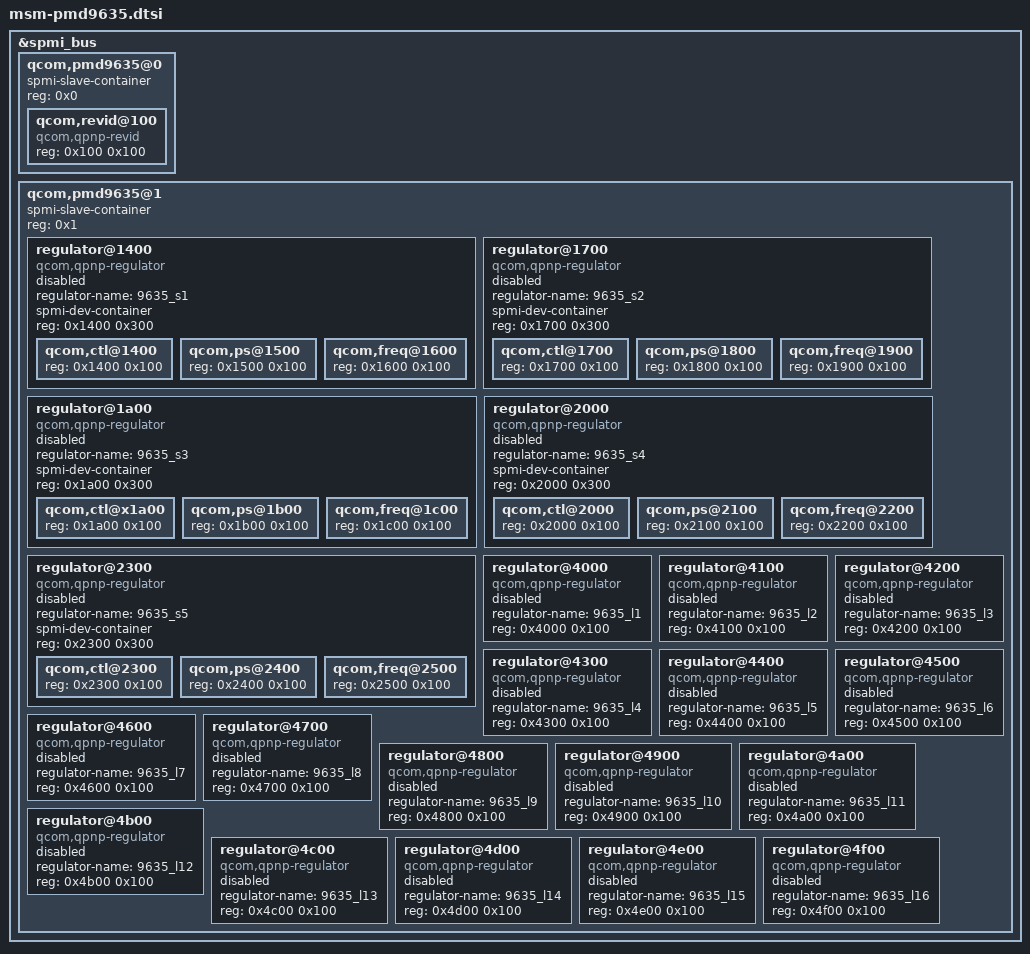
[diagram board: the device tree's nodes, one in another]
/* Copyright (c) 2013, The Linux Foundation. All rights reserved.
 *
 * This program is free software; you can redistribute it and/or modify
 * it under the terms of the GNU General Public License version 2 and
 * only version 2 as published by the Free Software Foundation.
 *
 * This program is distributed in the hope that it will be useful,
 * but WITHOUT ANY WARRANTY; without even the implied warranty of
 * MERCHANTABILITY or FITNESS FOR A PARTICULAR PURPOSE.  See the
 * GNU General Public License for more details.
 */

&spmi_bus {
	qcom,pmd9635@0 {
		spmi-slave-container;
		reg = <0x0>;
		#address-cells = <1>;
		#size-cells = <1>;

		qcom,revid@100 {
			compatible = "qcom,qpnp-revid";
			reg = <0x100 0x100>;
		};
	};

	qcom,pmd9635@1 {
		spmi-slave-container;
		reg = <0x1>;
		#address-cells = <1>;
		#size-cells = <1>;

		regulator@1400 {
			compatible = "qcom,qpnp-regulator";
			regulator-name = "9635_s1";
			spmi-dev-container;
			#address-cells = <1>;
			#size-cells = <1>;
			reg = <0x1400 0x300>;
			status = "disabled";

			qcom,ctl@1400 {
				reg = <0x1400 0x100>;
			};
			qcom,ps@1500 {
				reg = <0x1500 0x100>;
			};
			qcom,freq@1600 {
				reg = <0x1600 0x100>;
			};
		};

		regulator@1700 {
			compatible = "qcom,qpnp-regulator";
			regulator-name = "9635_s2";
			spmi-dev-container;
			#address-cells = <1>;
			#size-cells = <1>;
			reg = <0x1700 0x300>;
			status = "disabled";

			qcom,ctl@1700 {
				reg = <0x1700 0x100>;
			};
			qcom,ps@1800 {
				reg = <0x1800 0x100>;
			};
			qcom,freq@1900 {
				reg = <0x1900 0x100>;
			};
		};

		regulator@1a00 {
			compatible = "qcom,qpnp-regulator";
			regulator-name = "9635_s3";
			spmi-dev-container;
			#address-cells = <1>;
			#size-cells = <1>;
			reg = <0x1a00 0x300>;
			status = "disabled";

			qcom,ctl@x1a00 {
				reg = <0x1a00 0x100>;
			};
			qcom,ps@1b00 {
				reg = <0x1b00 0x100>;
			};
			qcom,freq@1c00 {
				reg = <0x1c00 0x100>;
			};
		};

		regulator@2000 {
			compatible = "qcom,qpnp-regulator";
			regulator-name = "9635_s4";
			spmi-dev-container;
			#address-cells = <1>;
			#size-cells = <1>;
			reg = <0x2000 0x300>;
			status = "disabled";

			qcom,ctl@2000 {
				reg = <0x2000 0x100>;
			};
			qcom,ps@2100 {
				reg = <0x2100 0x100>;
			};
			qcom,freq@2200 {
				reg = <0x2200 0x100>;
			};
		};

		regulator@2300 {
			compatible = "qcom,qpnp-regulator";
			regulator-name = "9635_s5";
			spmi-dev-container;
			#address-cells = <1>;
			#size-cells = <1>;
			reg = <0x2300 0x300>;
			status = "disabled";

			qcom,ctl@2300 {
				reg = <0x2300 0x100>;
			};
			qcom,ps@2400 {
				reg = <0x2400 0x100>;
			};
			qcom,freq@2500 {
				reg = <0x2500 0x100>;
			};
		};

		regulator@4000 {
			compatible = "qcom,qpnp-regulator";
			regulator-name = "9635_l1";
			reg = <0x4000 0x100>;
			status = "disabled";
		};

		regulator@4100 {
			compatible = "qcom,qpnp-regulator";
			regulator-name = "9635_l2";
			reg = <0x4100 0x100>;
			status = "disabled";
		};

		regulator@4200 {
			compatible = "qcom,qpnp-regulator";
			regulator-name = "9635_l3";
			reg = <0x4200 0x100>;
			status = "disabled";
		};

		regulator@4300 {
			compatible = "qcom,qpnp-regulator";
			regulator-name = "9635_l4";
			reg = <0x4300 0x100>;
			status = "disabled";
		};

		regulator@4400 {
			compatible = "qcom,qpnp-regulator";
			regulator-name = "9635_l5";
			reg = <0x4400 0x100>;
			status = "disabled";
		};

		regulator@4500 {
			compatible = "qcom,qpnp-regulator";
			regulator-name = "9635_l6";
			reg = <0x4500 0x100>;
			status = "disabled";
		};

		regulator@4600 {
			compatible = "qcom,qpnp-regulator";
			regulator-name = "9635_l7";
			reg = <0x4600 0x100>;
			status = "disabled";
		};

		regulator@4700 {
			compatible = "qcom,qpnp-regulator";
			regulator-name = "9635_l8";
			reg = <0x4700 0x100>;
			status = "disabled";
		};

		regulator@4800 {
			compatible = "qcom,qpnp-regulator";
			regulator-name = "9635_l9";
			reg = <0x4800 0x100>;
			status = "disabled";
		};

		regulator@4900 {
			compatible = "qcom,qpnp-regulator";
			regulator-name = "9635_l10";
			reg = <0x4900 0x100>;
			status = "disabled";
		};

		regulator@4a00 {
			compatible = "qcom,qpnp-regulator";
			regulator-name = "9635_l11";
			reg = <0x4a00 0x100>;
			status = "disabled";
		};

		regulator@4b00 {
			compatible = "qcom,qpnp-regulator";
			regulator-name = "9635_l12";
			reg = <0x4b00 0x100>;
			status = "disabled";
		};

		regulator@4c00 {
			compatible = "qcom,qpnp-regulator";
			regulator-name = "9635_l13";
			reg = <0x4c00 0x100>;
			status = "disabled";
		};

		regulator@4d00 {
			compatible = "qcom,qpnp-regulator";
			regulator-name = "9635_l14";
			reg = <0x4d00 0x100>;
			status = "disabled";
		};

		regulator@4e00 {
			compatible = "qcom,qpnp-regulator";
			regulator-name = "9635_l15";
			reg = <0x4e00 0x100>;
			status = "disabled";
		};

		regulator@4f00 {
			compatible = "qcom,qpnp-regulator";
			regulator-name = "9635_l16";
			reg = <0x4f00 0x100>;
			status = "disabled";
		};
	};
};
